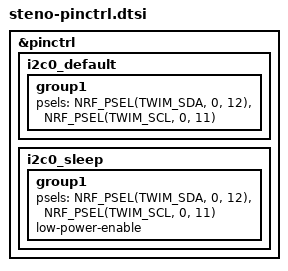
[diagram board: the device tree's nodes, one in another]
/*
 * Pin assignments taken from the board's own steno-pinctrl.dtsi:
 * I2C0 SDA = P0.12, SCL = P0.11, no internal pull-ups (external ones fitted).
 * SPDX-License-Identifier: MIT
 */
&pinctrl {
	i2c0_default: i2c0_default {
		group1 {
			psels = <NRF_PSEL(TWIM_SDA, 0, 12)>,
				<NRF_PSEL(TWIM_SCL, 0, 11)>;
		};
	};

	i2c0_sleep: i2c0_sleep {
		group1 {
			psels = <NRF_PSEL(TWIM_SDA, 0, 12)>,
				<NRF_PSEL(TWIM_SCL, 0, 11)>;
			low-power-enable;
		};
	};
};
